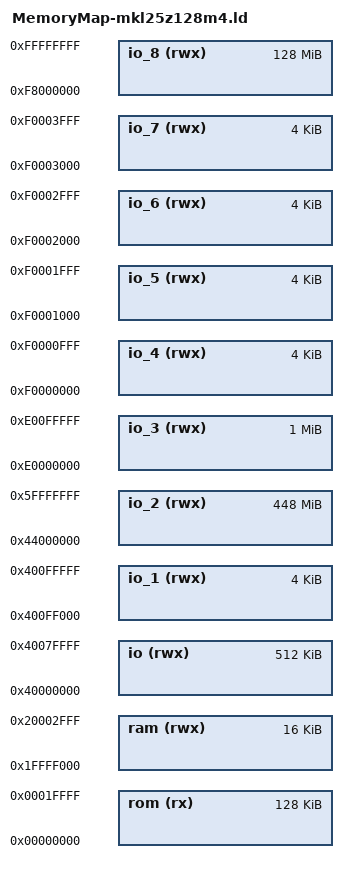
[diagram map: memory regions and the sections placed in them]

/* ---- <<< Use Configuration Wizard in Context Menu >>> ---- */

/* <o> Stack Size
   <i> Required amount of stack space  
   <0x0-0x4000> 
*/
__stack_size = 0x1000;

/* <o> GDB stack fix 
   <i> A small amount of reserve RAM used to prevent an Eclipse GDB bug that occurs when the stack is near unallocated memory
   <0-32> 
*/
__gdbstack_fix = 8;

/* <o> Minimum Heap Size 
   <i> Actual heap may be larger as it fills all unused RAM 
   <0x0-0x4000> 
*/
__heap_size  = 0x1000;

/* <h>RAM region used for stack and heap   <o0>  start <o1> length  </h> */
/* <h>Flash region used for code, data etc.<o2>  start <o3> length  </h> */
/*
 * Memory Map generated by USBDM New Project Wizard for MKL25Z128M4
 */
MEMORY
{
  ram        (rwx) : ORIGIN = 0x1FFFF000, LENGTH = 0x00004000
  rom        (rx)  : ORIGIN = 0x00000000, LENGTH = 0x00020000
  io         (rwx) : ORIGIN = 0x40000000, LENGTH = 0x00080000
  io_1       (rwx) : ORIGIN = 0x400FF000, LENGTH = 0x00001000
  io_2       (rwx) : ORIGIN = 0x44000000, LENGTH = 0x1C000000
  io_3       (rwx) : ORIGIN = 0xE0000000, LENGTH = 0x00100000
  io_4       (rwx) : ORIGIN = 0xF0000000, LENGTH = 0x00001000
  io_5       (rwx) : ORIGIN = 0xF0001000, LENGTH = 0x00001000
  io_6       (rwx) : ORIGIN = 0xF0002000, LENGTH = 0x00001000
  io_7       (rwx) : ORIGIN = 0xF0003000, LENGTH = 0x00001000
  io_8       (rwx) : ORIGIN = 0xF8000000, LENGTH = 0x08000000
};


